# R7FA4L1BD register map
Vendor: Renesas Electronics Corporation; Series: RA4; File version: 0.90.02
CPU: CM33 r0p4, little endian, MPU, FPU, VTOR, 4 interrupt priority bits, 96 interrupts
Registers are 32-bit, read-write, reset 0x0 unless marked. A register's access mark holds for its fields unless they carry their own. Offsets are from the block's base; [hi:lo] are bit positions; {n}, {i} and the like mark numbered series.

## CRC — Cyclic Redundancy Check Calculator
Base 0x40108000
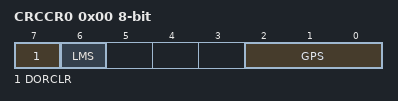
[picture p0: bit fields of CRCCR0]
0x00 CRCCR0 8-bit — CRC Control Register 0
  [7] DORCLR wo — CRCDOR/CRCDOR_HA/CRCDOR_BY Register Clear
  [6] LMS — CRC Calculation Switching
  [2:0] GPS — CRC Generating Polynomial Switching
0x04 CRCDIR — CRC Data Input Register
0x04 CRCDIR_BY 8-bit (alternate view of CRCDIR) — CRC Data Input Register
0x08 CRCDOR — CRC Data Output Register
0x08 CRCDOR_HA 16-bit (alternate view of CRCDOR) — CRC Data Output Register
0x08 CRCDOR_BY 8-bit (alternate view of CRCDOR) — CRC Data Output Register

## DOC_B — Data Operation Circuit
Base 0x40109000
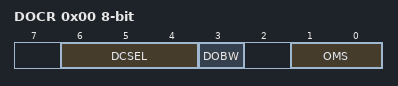
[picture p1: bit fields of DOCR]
0x00 DOCR 8-bit — DOC Control Register
  [6:4] DCSEL — Detection Condition Select
  [3] DOBW — Data Operation Bit Width Select
  [1:0] OMS — Operating Mode Select
0x04 DOSR 8-bit ro — DOC Flag Status Register
  [0] DOPCF — Data Operation Circuit Flag
0x08 DOSCR 8-bit wo — DOC Flag Status Clear Register
  [0] DOPCFCL — DOPCF Clear
0x0C DODIR — DOC Data Input Register
0x10 DODSR0 — DOC Data Setting Register 0
0x14 DODSR1 — DOC Data Setting Register 1

## SPI0 — Serial Peripheral Interface
Base 0x4011A000
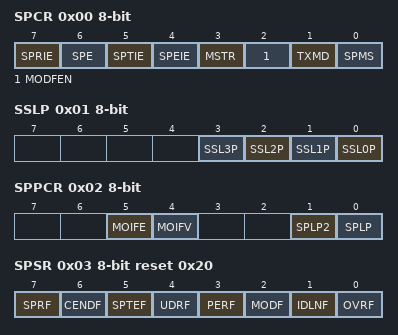
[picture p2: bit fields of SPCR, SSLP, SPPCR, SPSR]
0x00 SPCR 8-bit — SPI Control Register
  [7] SPRIE — SPI Receive Buffer Full Interrupt Enable
  [6] SPE — SPI Function Enable
  [5] SPTIE — Transmit Buffer Empty Interrupt Enable
  [4] SPEIE — SPI Error Interrupt Enable
  [3] MSTR — SPI Master/Slave Mode Select
  [2] MODFEN — Mode Fault Error Detection Enable
  [1] TXMD — Communications Operating Mode Select
  [0] SPMS — SPI Mode Select
0x01 SSLP 8-bit — SPI Slave Select Polarity Register
  [n] SSL{n}P (n=0..3) — SSLn{n} Signal Polarity Setting
0x02 SPPCR 8-bit — SPI Pin Control Register
  [5] MOIFE — MOSI Idle Value Fixing Enable
  [4] MOIFV — MOSI Idle Fixed Value
  [1] SPLP2 — SPI Loopback 2
  [0] SPLP — SPI Loopback
0x03 SPSR 8-bit reset 0x20 — SPI Status Register
  [7] SPRF — SPI Receive Buffer Full Flag
  [6] CENDF — Communication End Flag
  [5] SPTEF — SPI Transmit Buffer Empty Flag
  [4] UDRF — Underrun Error Flag
  [3] PERF — Parity Error Flag
  [2] MODF — Mode Fault Error Flag
  [1] IDLNF ro — SPI Idle Flag
  [0] OVRF — Overrun Error Flag
0x04 SPDR — SPI Data Register
0x04 SPDR_HA 16-bit (alternate view of SPDR) — SPI Data Register
0x04 SPDR_BY 8-bit (alternate view of SPDR) — SPI Data Register
0x08 SPSCR 8-bit — SPI Sequence Control Register
  [2:0] SPSLN — SPI Sequence Length Specification
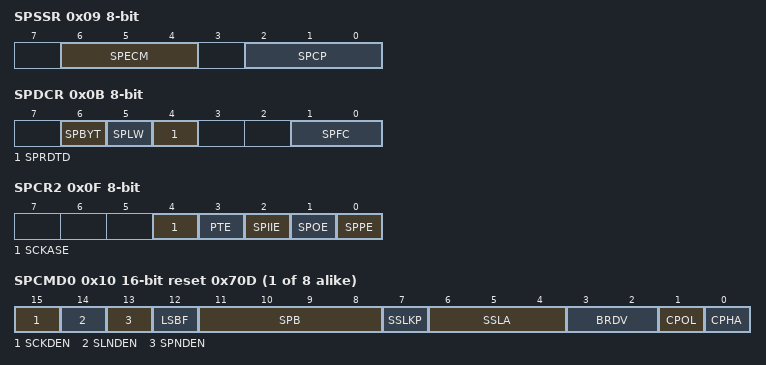
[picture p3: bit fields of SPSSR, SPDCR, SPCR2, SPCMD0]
0x09 SPSSR 8-bit ro — SPI Sequence Status Register
  [6:4] SPECM — SPI Error Command
  [2:0] SPCP — SPI Command Pointer
0x0A SPBR 8-bit reset 0xFF — SPI Bit Rate Register
0x0B SPDCR 8-bit — SPI Data Control Register
  [6] SPBYT — SPI Byte Access Specification
  [5] SPLW — SPI Word Access/Halfword Access Specification
  [4] SPRDTD — SPI Receive/Transmit Data Select
  [1:0] SPFC — Number of Frames Specification
0x0C SPCKD 8-bit — SPI Clock Delay Register
  [2:0] SCKDL — RSPCK Delay Setting
0x0D SSLND 8-bit — SPI Slave Select Negation Delay Register
  [2:0] SLNDL — SSL Negation Delay Setting
0x0E SPND 8-bit — SPI Next,Access Delay Register
  [2:0] SPNDL — SPI Next,Access Delay Setting
0x0F SPCR2 8-bit — SPI Control Register 2
  [4] SCKASE — RSPCK Auto,Stop Function Enable
  [3] PTE — Parity Self,Testing
  [2] SPIIE — SPI Idle Interrupt Enable
  [1] SPOE — Parity Mode
  [0] SPPE — Parity Enable
{0x10+2i} SPCMD{i} (i=0..7) 16-bit reset 0x70D — SPI Command Register {i}
  [15] SCKDEN — RSPCK Delay Setting Enable
  [14] SLNDEN — SSL Negation Delay Setting Enable
  [13] SPNDEN — SPI Next,Access Delay Enable
  [12] LSBF — SPI LSB First
  [11:8] SPB — SPI Data Length Setting
  [7] SSLKP — SSL Signal Level Keeping
  [6:4] SSLA — SSL Signal Assertion Setting
  [3:2] BRDV — Bit Rate Division Setting
  [1] CPOL — RSPCK Polarity Setting
  [0] CPHA — RSPCK Phase Setting
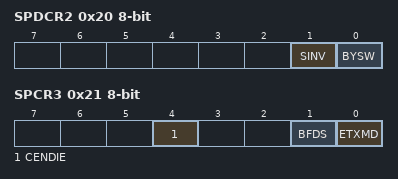
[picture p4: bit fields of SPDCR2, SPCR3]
0x20 SPDCR2 8-bit — SPI Data Control Register 2
  [1] SINV — Serial Data Invert Bit
  [0] BYSW — Byte Swap Operating Mode Select
0x21 SPCR3 8-bit — SPI Control Register 3
  [4] CENDIE — SPI Communication End Interrupt Enable
  [1] BFDS — Between Burst Transfer Frames Delay Select
  [0] ETXMD — Extended Communication Mode Select
